# MKE14Z7 register map
Vendor: Freescale Semiconductor, Inc.; Series: Kinetis_E; File version: 1.6
CPU: CM0PLUS r0p0, little endian, no MPU, no FPU, VTOR, 2 interrupt priority bits
Registers are 32-bit, read-write, reset 0x0 unless marked. A register's access mark holds for its fields unless they carry their own. Offsets are from the block's base; [hi:lo] are bit positions; {n}, {i} and the like mark numbered series.

## LPTMR0 — Low Power Timer
Base 0x40040000; register names take the prefix LPTMR0_
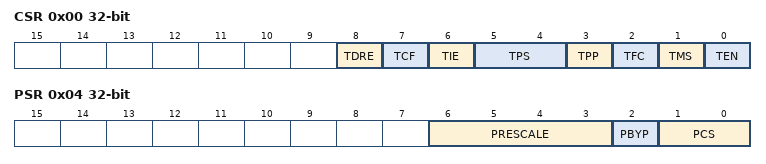
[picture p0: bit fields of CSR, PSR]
0x00 CSR — Low Power Timer Control Status Register
  [8] TDRE — Timer DMA Request Enable
    0=Timer DMA Request disabled; 1=Timer DMA Request enabled
  [7] TCF — Timer Compare Flag
    0=The value of CNR is not equal to CMR and increments; 1=The value of CNR is equal to CMR and increments
  [6] TIE — Timer Interrupt Enable
    0=Timer interrupt disabled; 1=Timer interrupt enabled
  [5:4] TPS — Timer Pin Select
    {v}=Pulse counter input {v} is selected (v=0..3)
  [3] TPP — Timer Pin Polarity
    0=Pulse Counter input source is active-high, and the CNR will increment on the rising-edge; 1=Pulse Counter input source is active-low, and the CNR will increment on the falling-edge
  [2] TFC — Timer Free-Running Counter
    0=CNR is reset whenever TCF is set; 1=CNR is reset on overflow
  [1] TMS — Timer Mode Select
    0=Time Counter mode; 1=Pulse Counter mode
  [0] TEN — Timer Enable
    0=LPTMR is disabled and internal logic is reset; 1=LPTMR is enabled
0x04 PSR — Low Power Timer Prescale Register
  [6:3] PRESCALE — Prescale Value
    0=Prescaler divides the prescaler clock by 2; glitch filter does not support this configuration; 1=Prescaler divides the prescaler clock by 4; glitch filter recognizes change on input pin after 2 rising clock edges; 2=Prescaler divides the prescaler clock by 8; glitch filter recognizes change on input pin after 4 rising clock edges; 3=Prescaler divides the prescaler clock by 16; glitch filter recognizes change on input pin after 8 rising clock edges; 4=Prescaler divides the prescaler clock by 32; glitch filter recognizes change on input pin after 16 rising clock edges; 5=Prescaler divides the prescaler clock by 64; glitch filter recognizes change on input pin after 32 rising clock edges; 6=Prescaler divides the prescaler clock by 128; glitch filter recognizes change on input pin after 64 rising clock edges; 7=Prescaler divides the prescaler clock by 256; glitch filter recognizes change on input pin after 128 rising clock edges; 8=Prescaler divides the prescaler clock by 512; glitch filter recognizes change on input pin after 256 rising clock edges; 9=Prescaler divides the prescaler clock by 1024; glitch filter recognizes change on input pin after 512 rising clock edges; 10=Prescaler divides the prescaler clock by 2048; glitch filter recognizes change on input pin after 1024 rising clock edges; 11=Prescaler divides the prescaler clock by 4096; glitch filter recognizes change on input pin after 2048 rising clock edges; 12=Prescaler divides the prescaler clock by 8192; glitch filter recognizes change on input pin after 4096 rising clock edges; 13=Prescaler divides the prescaler clock by 16,384; glitch filter recognizes change on input pin after 8192 rising clock edges; 14=Prescaler divides the prescaler clock by 32,768; glitch filter recognizes change on input pin after 16,384 rising clock edges; 15=Prescaler divides the prescaler clock by 65,536; glitch filter recognizes change on input pin after 32,768 rising clock edges
  [2] PBYP — Prescaler Bypass
    0=Prescaler/glitch filter is enabled; 1=Prescaler/glitch filter is bypassed
  [1:0] PCS — Prescaler Clock Select
    {v}=Prescaler/glitch filter clock {v} selected (v=0..3)
0x08 CMR — Low Power Timer Compare Register
  [15:0] COMPARE — Compare Value
0x0C CNR — Low Power Timer Counter Register
  [15:0] COUNTER — Counter Value

## WDOG — Watchdog timer
Base 0x40052000; register names take the prefix WDOG_
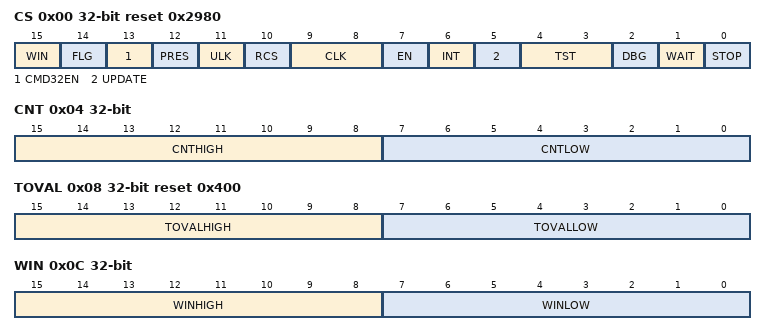
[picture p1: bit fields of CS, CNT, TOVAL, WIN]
0x00 CS reset 0x2980 — Watchdog Control and Status Register
  [15] WIN — Watchdog Window
    0=Window mode disabled; 1=Window mode enabled
  [14] FLG — Watchdog Interrupt Flag
    0=No interrupt occurred; 1=An interrupt occurred
  [13] CMD32EN — Enables or disables WDOG support for 32-bit (or 16-bit or 8-bit) refresh/unlock command write words
    0=Disables support for 32-bit (or 16-bit or 8-bit) refresh/unlock command write words; 1=Enables support for 32-bit (or 16-bit or 8-bit) refresh/unlock command write words
  [12] PRES — Watchdog prescaler
    0=256 prescaler disabled; 1=256 prescaler enabled
  [11] ULK ro — Unlock status
    0=WDOG is locked; 1=WDOG is unlocked
  [10] RCS ro — Reconfiguration Success
    0=Reconfiguring WDOG; 1=Reconfiguration is successful
  [9:8] CLK — Watchdog Clock
    0=Bus clock; 1=LPO clock (128k LPO, 32k LPO, 1k LPO, or 32k OSC), whose selection is controlled via SIM_LPOCLKS[LPOCLKSEL]; 2=System oscillator clock (SOSC, from SCG); 3=Slow internal reference clock (SIRC, from SCG)
  [7] EN — Watchdog Enable
    0=Watchdog disabled; 1=Watchdog enabled
  [6] INT — Watchdog Interrupt
    0=Watchdog interrupts are disabled. Watchdog resets are not delayed.; 1=Watchdog interrupts are enabled. Watchdog resets are delayed by 128 bus clocks from the interrupt vector fetch.
  [5] UPDATE — Allow updates
    0=Updates not allowed. After the initial configuration, the watchdog cannot be later modified without forcing a reset.; 1=Updates allowed. Software can modify the watchdog configuration registers within 128 bus clocks after performing the unlock write sequence.
  [4:3] TST — Watchdog Test
    0=Watchdog test mode disabled; 1=Watchdog user mode enabled. (Watchdog test mode disabled.) After testing the watchdog, software should use this setting to indicate that the watchdog is functioning normally in user mode.; 2=Watchdog test mode enabled, only the low byte is used. CNT[CNTLOW] is compared with TOVAL[TOVALLOW].; 3=Watchdog test mode enabled, only the high byte is used. CNT[CNTHIGH] is compared with TOVAL[TOVALHIGH].
  [2] DBG — Debug Enable
    0=Watchdog disabled in chip debug mode; 1=Watchdog enabled in chip debug mode
  [1] WAIT — Wait Enable
    0=Watchdog disabled in chip wait mode; 1=Watchdog enabled in chip wait mode
  [0] STOP — Stop Enable
    0=Watchdog disabled in chip stop mode; 1=Watchdog enabled in chip stop mode
0x04 CNT — Watchdog Counter Register
  [15:8] CNTHIGH — High byte of the Watchdog Counter
  [7:0] CNTLOW — Low byte of the Watchdog Counter
0x08 TOVAL reset 0x400 — Watchdog Timeout Value Register
  [15:8] TOVALHIGH — High byte of the timeout value
  [7:0] TOVALLOW — Low byte of the timeout value
0x0C WIN — Watchdog Window Register
  [15:8] WINHIGH — High byte of Watchdog Window
  [7:0] WINLOW — Low byte of Watchdog Window
